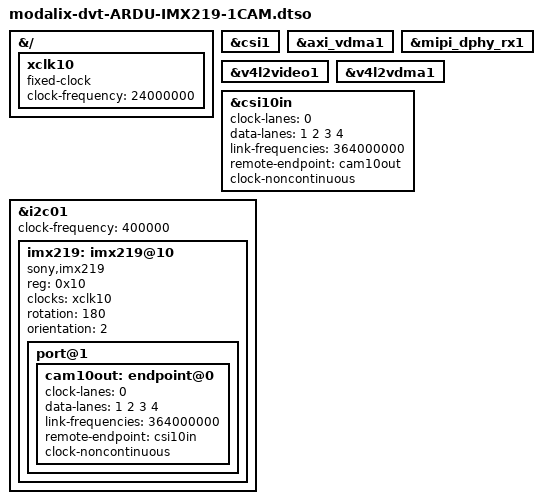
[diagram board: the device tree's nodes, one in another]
// SPDX-License-Identifier: (GPL-2.0+ OR MIT)
/*
 * Copyright (c) 2026 SiMa ai
 */

/dts-v1/;
/plugin/;

&{/} {
        xclk10: xclk10 {
                status = "okay";
                compatible = "fixed-clock";
                #clock-cells = <0>;
                clock-frequency = <24000000>;
        };
};

&csi1 {
    status = "okay";
};

&axi_vdma1 {
    status = "okay";
};

&mipi_dphy_rx1 {
    status = "okay";
};

&v4l2video1 {
    status = "okay";
};

&v4l2vdma1 {
    status = "okay";
};

&csi10in{
    clock-lanes = <0>;
    data-lanes = <1 2 3 4>;
    link-frequencies = /bits/ 64 <364000000>;
    remote-endpoint = <&cam10out>;
    clock-noncontinuous;
};

&i2c01 {
        status = "okay";
        clock-frequency = <400000>;
        #address-cells = <1>;
        #size-cells = <0>;

        imx219: imx219@10 {
                compatible = "sony,imx219";
                reg = <0x10>;

                clocks = <&xclk10>;
                clock-names = "xclk";

                rotation = <180>;
                orientation = <2>;

                port@1 {
                        cam10out: endpoint@0 {
                                clock-lanes = <0>;
                                data-lanes = <1 2 3 4>;
                                link-frequencies = /bits/ 64 <364000000>;
                                remote-endpoint = <&csi10in>;
                                clock-noncontinuous;
                        };
                };
        };
};
